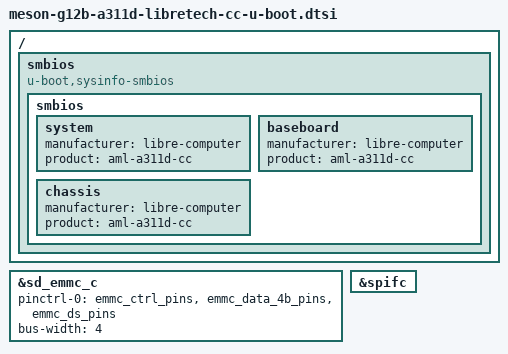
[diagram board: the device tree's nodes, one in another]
// SPDX-License-Identifier: (GPL-2.0+ OR MIT)
/*
 * Copyright (c) 2023 Neil Armstrong <neil.armstrong@linaro.org>
 */

#include "meson-g12-common-u-boot.dtsi"

/ {
	smbios {
		compatible = "u-boot,sysinfo-smbios";

		smbios {
			system {
				manufacturer = "libre-computer";
				product = "aml-a311d-cc";
			};

			baseboard {
				manufacturer = "libre-computer";
				product = "aml-a311d-cc";
			};

			chassis {
				manufacturer = "libre-computer";
				product = "aml-a311d-cc";
			};
		};
	};
};

&sd_emmc_c {
	pinctrl-0 = <&emmc_ctrl_pins>, <&emmc_data_4b_pins>, <&emmc_ds_pins>;
	bus-width = <4>;
};

&spifc {
	status = "okay";
};
